# haltium_cellrf register map
Vendor: Nordic Semiconductor; Series: nRFHaltium; File version: 1
CPU: CM0 r0p0, little endian, no MPU, no FPU, 2 interrupt priority bits, 33 interrupts
Registers are 32-bit, read-write, reset 0x0 unless marked. A register's access mark holds for its fields unless they carry their own. Offsets are from the block's base; [hi:lo] are bit positions; lines under a group give offsets from that group; {n}, {i} and the like mark numbered series; 'fields as' and 'values as' point back to an identical list.

## DSA2TX — Direct Sequence Access controller, version 2 0
Base 0x46040000
Same registers: DSA2RX 0x46042000
{0x0+4i} TASKS_START[{i}] (i=0..13) wo — Description collection: SW trigger for channel n
  [0] TASKS_START — SW trigger for channel n
    1=Trigger task
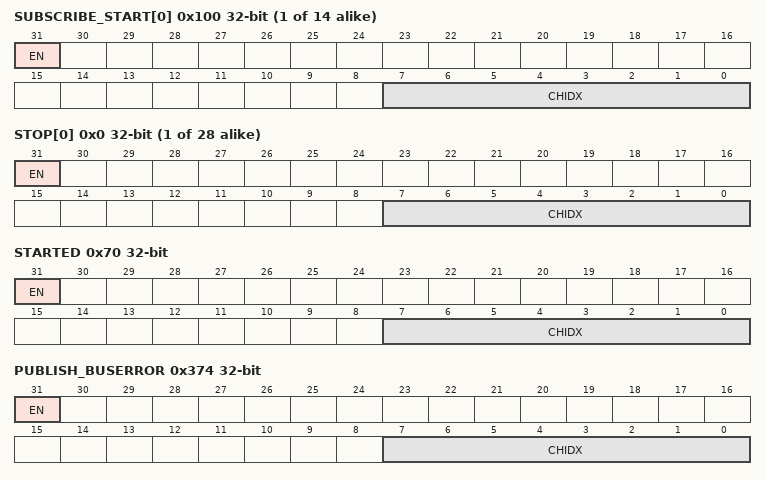
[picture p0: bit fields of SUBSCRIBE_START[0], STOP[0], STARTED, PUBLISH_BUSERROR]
{0x100+4i} SUBSCRIBE_START[{i}] (i=0..13) — Description collection: Subscribe configuration for task START[n]
  [31] EN
    0=Disabled (Disable subscription); 1=Enabled (Enable subscription)
  [7:0] CHIDX — DPPI channel that task START[n] will subscribe to
0x200 EVENTS_CHANNEL group — Peripheral events.
  {0x0+4j} STOP[{j}] (j=0..27) — Description collection: DSA stopped for channel n
    [0] STOP — DSA stopped for channel n
      0=NotGenerated (Event not generated); 1=Generated (Event generated)
  0x70 STARTED — DSA started executing a channel
    [0] STARTED
      values as EVENTS_CHANNEL.STOP[0].STOP
0x274 EVENTS_BUSERROR — A bus error has occurred on either the RAM or the RF bus
  [0] EVENTS_BUSERROR
    values as EVENTS_CHANNEL.STOP[0].STOP
0x278 EVENTS_DECODEERROR — An invalid instruction was decoded.
  [0] EVENTS_DECODEERROR
    values as EVENTS_CHANNEL.STOP[0].STOP
0x27C EVENTS_PENDINGTRIGGERED — A channel that was already pending was triggered again; this will not cause the channel to be re-executed.
  [0] EVENTS_PENDINGTRIGGERED
    values as EVENTS_CHANNEL.STOP[0].STOP
0x300 PUBLISH_CHANNEL group — Publish configuration for events
  {0x0+4j} STOP[{j}] (j=0..27) — Description collection: Publish configuration for event CHANNEL.STOP[n][n]
    [31] EN
      0=Disabled (Disable publishing); 1=Enabled (Enable publishing)
    [7:0] CHIDX — DPPI channel that event CHANNEL.STOP[n][n] will publish to
  0x70 STARTED — Publish configuration for event CHANNEL.STARTED
    [31] EN
      values as PUBLISH_CHANNEL.STOP[0].EN
    [7:0] CHIDX — DPPI channel that event CHANNEL.STARTED will publish to
0x374 PUBLISH_BUSERROR — Publish configuration for event BUSERROR
  [31] EN
    values as PUBLISH_CHANNEL.STOP[0].EN
  [7:0] CHIDX — DPPI channel that event BUSERROR will publish to
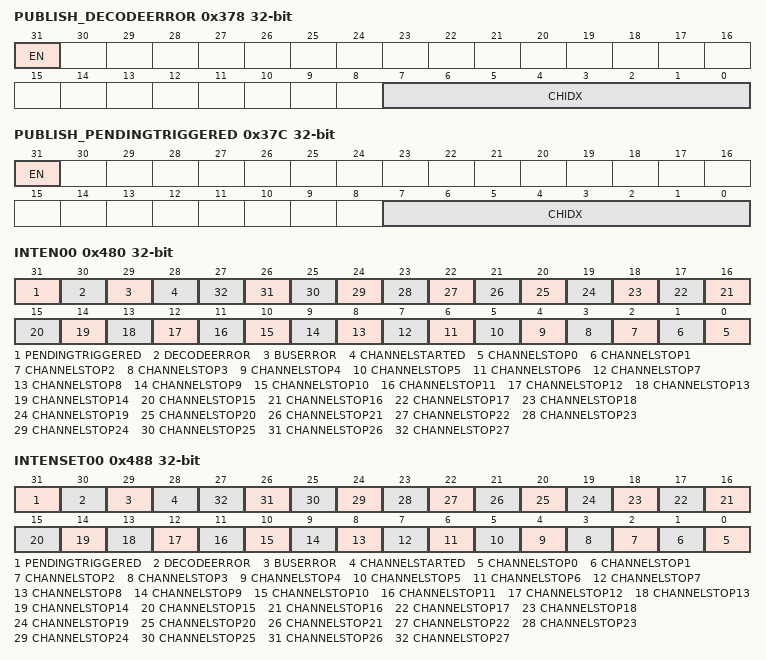
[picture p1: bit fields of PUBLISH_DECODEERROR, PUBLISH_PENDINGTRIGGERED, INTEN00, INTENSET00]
0x378 PUBLISH_DECODEERROR — Publish configuration for event DECODEERROR
  [31] EN
    values as PUBLISH_CHANNEL.STOP[0].EN
  [7:0] CHIDX — DPPI channel that event DECODEERROR will publish to
0x37C PUBLISH_PENDINGTRIGGERED — Publish configuration for event PENDINGTRIGGERED
  [31] EN
    values as PUBLISH_CHANNEL.STOP[0].EN
  [7:0] CHIDX — DPPI channel that event PENDINGTRIGGERED will publish to
0x480 INTEN00 — Enable or disable interrupt
  [all] fields
    0=Disabled; 1=Enabled
  [31] PENDINGTRIGGERED — Enable or disable interrupt for event PENDINGTRIGGERED
  [30] DECODEERROR — Enable or disable interrupt for event DECODEERROR
  [29] BUSERROR — Enable or disable interrupt for event BUSERROR
  [28] CHANNELSTARTED — Enable or disable interrupt for event CHANNELSTARTED
  [n] CHANNELSTOP{n} (n=0..27) — Enable or disable interrupt for event CHANNELSTOP[{n}]
0x484 INTEN01 — Enable or disable interrupt
0x488 INTENSET00 — Enable interrupt
  [all] fields
    on read: 0=Disabled (Read: Disabled); 1=Enabled (Read: Enabled) | on write: 1=Set (Enable)
  [31] PENDINGTRIGGERED — Write '1' to enable interrupt for event PENDINGTRIGGERED
  [30] DECODEERROR — Write '1' to enable interrupt for event DECODEERROR
  [29] BUSERROR — Write '1' to enable interrupt for event BUSERROR
  [28] CHANNELSTARTED — Write '1' to enable interrupt for event CHANNELSTARTED
  [n] CHANNELSTOP{n} (n=0..27) — Write '1' to enable interrupt for event CHANNELSTOP[{n}]
0x48C INTENSET01 — Enable interrupt
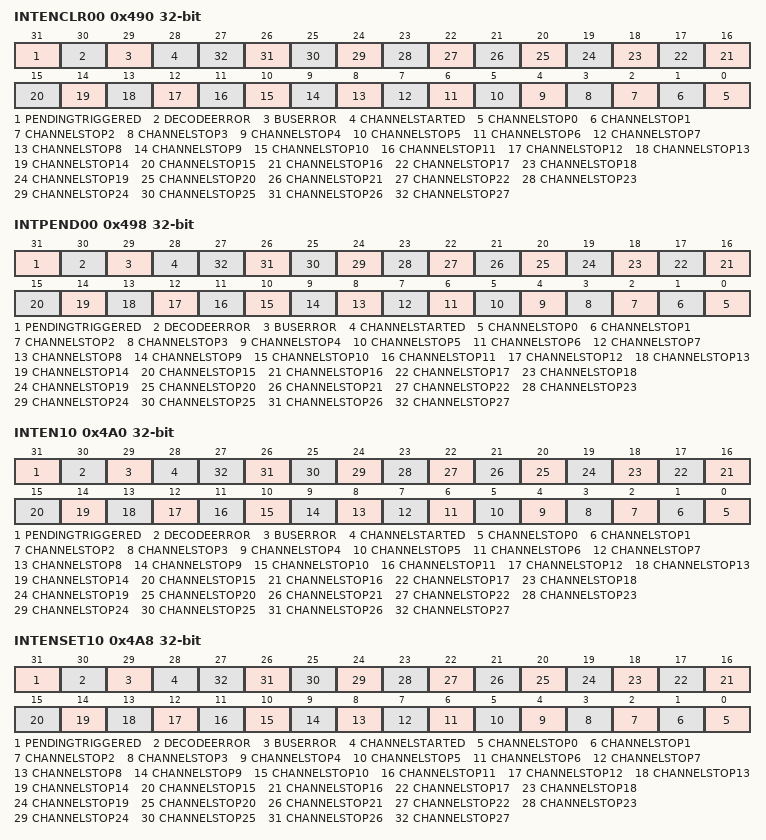
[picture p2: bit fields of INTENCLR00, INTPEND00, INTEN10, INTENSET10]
0x490 INTENCLR00 — Disable interrupt
  [all] fields
    on read: 0=Disabled (Read: Disabled); 1=Enabled (Read: Enabled) | on write: 1=Clear (Disable)
  [31] PENDINGTRIGGERED — Write '1' to disable interrupt for event PENDINGTRIGGERED
  [30] DECODEERROR — Write '1' to disable interrupt for event DECODEERROR
  [29] BUSERROR — Write '1' to disable interrupt for event BUSERROR
  [28] CHANNELSTARTED — Write '1' to disable interrupt for event CHANNELSTARTED
  [n] CHANNELSTOP{n} (n=0..27) — Write '1' to disable interrupt for event CHANNELSTOP[{n}]
0x494 INTENCLR01 — Disable interrupt
0x498 INTPEND00 ro — Pending interrupts
  [all] fields
    on read: 0=NotPending (Read: Not pending); 1=Pending (Read: Pending)
  [31] PENDINGTRIGGERED — Read pending status of interrupt for event PENDINGTRIGGERED
  [30] DECODEERROR — Read pending status of interrupt for event DECODEERROR
  [29] BUSERROR — Read pending status of interrupt for event BUSERROR
  [28] CHANNELSTARTED — Read pending status of interrupt for event CHANNELSTARTED
  [n] CHANNELSTOP{n} (n=0..27) — Read pending status of interrupt for event CHANNELSTOP[{n}]
0x49C INTPEND01 ro — Pending interrupts
0x4A0 INTEN10 — Enable or disable interrupt
  fields as INTEN00
0x4A4 INTEN11 — Enable or disable interrupt
0x4A8 INTENSET10 — Enable interrupt
  fields as INTENSET00
0x4AC INTENSET11 — Enable interrupt
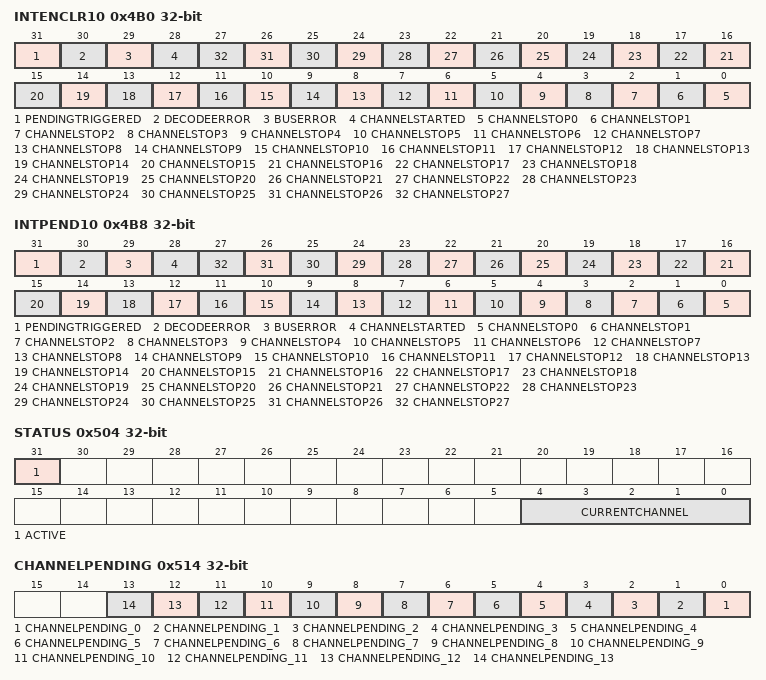
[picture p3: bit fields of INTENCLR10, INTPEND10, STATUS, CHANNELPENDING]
0x4B0 INTENCLR10 — Disable interrupt
  fields as INTENCLR00
0x4B4 INTENCLR11 — Disable interrupt
0x4B8 INTPEND10 ro — Pending interrupts
  fields as INTPEND00
0x4BC INTPEND11 ro — Pending interrupts
0x500 READDATA ro — Last data read on the RF bus
0x504 STATUS ro — Read DSA status of debug signals
  [31] ACTIVE — Status of dsaActive, i.e. an indication whether DSA2 is currently executing a sequence.
  [4:0] CURRENTCHANNEL — Number of the currently executing channel (0...NUM_CHANNEL-1). Note that this is only valid if DSA_ACTIVE is high.
0x508 LASTADDR ro reset 0x43000000 — Last address decoded from READ/WRITE/WRITE_INDIRECT instructions
0x50C XACTPENDING ro reset 0xFFFFFFFF — Address referred to by the first transaction that is active, or 0xFFFFFFFF if none.
0x510 BUSERRORADDR ro reset 0xFFFFFFFF — Address that triggered the latest bus error, or 0xFFFFFFFF if none.
0x514 CHANNELPENDING ro — DSA2 channel pending status register
  [all] fields
    0=NotPending (Channel is not pending); 1=Pending (Channel is pending waiting for other channels to finish first)
  [n] CHANNELPENDING_{n} (n=0..13) — Channel {n} pending status
0x600 ENABLE — DSA2 IP enable
  [0] ENABLE
    0=Reset (IP core synchronous reset); 1=Enable
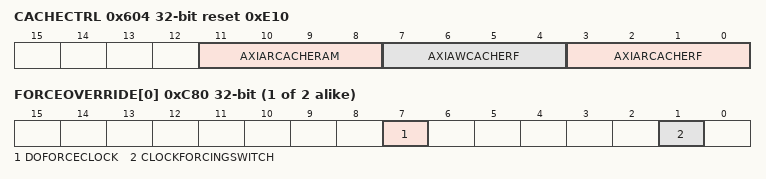
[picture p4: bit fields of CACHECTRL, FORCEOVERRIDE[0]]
0x604 CACHECTRL reset 0xE10 — DSA2 Cache control register
  [11:8] AXIARCACHERAM — Value for axiARCacheRam, see ARM IHI 0022F.b
    0=DevNoBuf (Device Non-bufferable); 1=DevBuf (Device bufferable); 2=NormNoCacheNoBuf (Normal Non-cacheable Non-bufferable); 3=NormNoCacheBuf (Normal Non-cacheable Bufferable); 10=Write-through No-allocate or Write-through Write-allocate; 11=Write-back No-allocate or Write-back Write-allocate; 14=Write-through Read-allocate or Write-through Read and Write-allocate; 15=Write-back Read-allocate or Write-back Read and Write-allocate
  [7:4] AXIAWCACHERF — Value for axiAWCacheRf, see ARM IHI 0022F.b
    0=DevNoBuf (Device Non-bufferable); 1=DevBuf (Device bufferable); 2=NormNoCacheNoBuf (Normal Non-cacheable Non-bufferable); 3=NormNoCacheBuf (Normal Non-cacheable Bufferable); 6=Write-through No-allocate or Write-through Read-allocate; 7=Write-back No-allocate or Write-back Read-allocate; 14=Write-through Write-allocate or Write-through Read and Write-allocate; 15=WriteBackWriteAlloc (Write-back Read and Write-allocate)
  [3:0] AXIARCACHERF — Value for axiARCacheRf, see ARM IHI 0022F.b
    values as AXIARCACHERAM
0x608 BUSERRORCFG reset 0x3 — Bus error handling configuration register
  [0] STOPONERROR — DSA2 should stop on bus errors
    0=Ignore bus errors, continue execution after a bus error; 1=Stop on bus errors from either the RAM or the RF bus
{0x700+4i} ADDRCONF[{i}] (i=0..13) — Description collection: Channel n start address configuration
  [11:0] CHANNELADDRESS — Channel n start address
{0x800+4i} PARAMREG[{i}] (i=0..39) — Description collection: Parameter register n for WRITE_INDIRECT
{0xC00+4i} PENALTYREG[{i}] (i=0..1) — Description collection: Penalty register for PCP n.
  [1:0] PENALTY — Penalty level.
    0=Full ((Auto 0) Full penalty); 1=Semi0 ((Auto 1) Semi (power on, clock off)); 2=Semi1 ((Auto 2) Semi (power on, clock core on, clock buffer off)); 3=Zero ((Auto 3) Zero penalty)
{0xC80+4i} FORCEOVERRIDE[{i}] (i=0..1) — Description collection: Force override register for PCP n.
  [7] DOFORCECLOCK — Enable/disable forcing of the clock request signals.
    0=Disabled; 1=Enabled
  [1] CLOCKFORCINGSWITCH — See DO_FORCE_CLOCK.
    0=Zero (clockRequest.switch = 0); 1=One (clockRequest.switch = 1)
